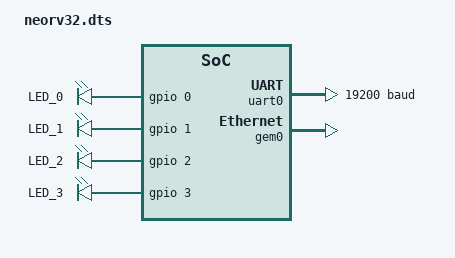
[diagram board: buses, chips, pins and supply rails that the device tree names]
/*
 * Copyright (c) 2021 Henrik Brix Andersen <henrik@brixandersen.dk>
 *
 * SPDX-License-Identifier: Apache-2.0
 */

/dts-v1/;

#include <neorv32.dtsi>
#include <freq.h>
#include <mem.h>
#include <zephyr/dt-bindings/ethernet/xlnx_gem.h>

/ {
	aliases {
		led0 = &led0;
		led1 = &led1;
		led2 = &led2;
		led3 = &led3;
	};

	chosen {
		zephyr,flash = &imem;
		zephyr,sram = &dmem;
		zephyr,console = &uart0;
		zephyr,shell-uart = &uart0;
//		zephyr,uart-pipe = &uart0;
		zephyr,ocm = &ocm_high;
	};

	soc {
		imem: memory@0 {
			compatible = "soc-nv-flash", "mmio-sram";
			reg = <0x0 DT_SIZE_K(256)>;
		};

		bootrom: memory@ffffc000 {
			compatible = "soc-nv-flash", "mmio-sram";
			reg = <0xffffc000 DT_SIZE_K(4)>;
		};

		dmem: memory@80000000 {
			compatible = "mmio-sram";
			reg = <0x80000000 DT_SIZE_K(64)>;
		};
	};

	leds {
		compatible = "gpio-leds";
		led0: led0 {
			gpios = <&gpio 0 GPIO_ACTIVE_HIGH>;
			label = "LED_0";
		};

		led1: led1 {
			gpios = <&gpio 1 GPIO_ACTIVE_HIGH>;
			label = "LED_1";
		};

		led2: led2 {
			gpios = <&gpio 2 GPIO_ACTIVE_HIGH>;
			label = "LED_2";
		};

		led3: led3 {
			gpios = <&gpio 3 GPIO_ACTIVE_HIGH>;
			label = "LED_3";
		};
	};
};

&cpu0 {
	clock-frequency = <DT_FREQ_M(100)>;
};

&uart0 {
	status = "okay";
	current-speed = <19200>;
};

&gpio_lo {
	status = "okay";
};

&gpio_hi {
	status = "okay";
};

&xirq {
	trigger-type = <0x00000000>;
};

&ext {
	gem0: ethernet@e000b000 {
		compatible = "xlnx,gem";
		reg = <0xe000b000 0x1000>, <0xf8000140 0x4>;
		interrupts = <0>, <1>;
		interrupt-names = "irq_0", "irq_1";
		init-mdio-phy;
		mdio-phy-address = <XLNX_GEM_PHY_AUTO_DETECT>;
		phy-poll-interval = <1000>;
		link-speed = <XLNX_GEM_LINK_SPEED_100MBIT>;
		amba-ahb-dbus-width = <XLNX_GEM_AMBA_AHB_DBUS_WIDTH_32BIT>;
		amba-ahb-burst-length = <XLNX_GEM_AMBA_AHB_BURST_SINGLE>;
		hw-rx-buffer-size = <XLNX_GEM_HW_RX_BUFFER_SIZE_8KB>;
		hw-rx-buffer-offset = <0>;
		hw-tx-buffer-size-full;
		rx-buffer-descriptors = <32>;
		tx-buffer-descriptors = <32>;
		rx-buffer-size = <512>;
		tx-buffer-size = <512>;
		discard-rx-fcs;
		unicast-hash;
		full-duplex;

		clock-frequency = <1000000000>;
		mdc-divider = <XLNX_GEM_MDC_DIVIDER_224>;
		local-mac-address = [00 0a 35 01 02 03];
 
		status = "okay";
//		status = "disabled";
	};

	slcr: slcr@f8000000 {
		#address-cells = <1>;
		#size-cells = <1>;
		compatible = "xlnx,zynq-slcr", "syscon";
		reg = <0xf8000000 0x1000>;
		ranges;

		pinctrl0: pinctrl@700 {
			compatible = "xlnx,pinctrl-zynq";
			reg = <0x700 0x200>;
			syscon = <&slcr>;
		};
	};

	ocm_high: memory@fffc0000 {
		compatible = "zephyr,memory-region";
		reg = <0xFFFC0000 DT_SIZE_K(128)>;
		zephyr,memory-region = "OCM_HIGH";
	};

};
